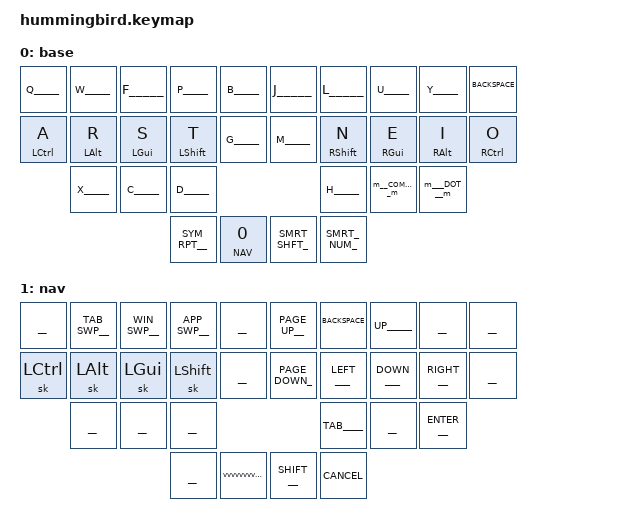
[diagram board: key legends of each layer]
/* source key position labels */
#include "zmk-helpers/key-labels/hummingbird.h"

#define MOUSE_IGNORED_KEYS LT1 LT3 RT0 RT1 RT2 RT3 RT4 RM1 RM2 RM3 RB1 RB2 RH0 RH1
#define REVERSE_SWAPPER RH0


/* source the base definitions */
#include "base.dtsi"

#define __LCTL__A__ &hml LCTL A
#define __LOPT__R__ &hml LALT R
#define __LGUI__S__ &hml LGUI S
#define __LSFT__T__ &hml LSHFT T
#define __RSFT__N__ &hmr RSHFT N
#define __RGUI__E__ &hmr RGUI E
#define __ROPT__I__ &hmr RALT I
#define __RCTL__O__ &hmr RCTL O

#define __SPC_NAV__ &lt_spc NAV 0
#define __SYM_RPT__ &lt SYM &key_repeat

ZMK_CONDITIONAL_LAYER(sys, SYM NUM, SYS)  // FN + NUM --> SYS

ZMK_LAYER(base,
//╭─────────────┬─────────────────────────────────────────┬─────────────╮ ╭─────────────┬───────────────────────────┬─────────────┬─────────────╮
    _____Q_____   _____W_____   _____F_____   _____P_____   _____B_____     _____J_____   _____L_____   _____U_____   _____Y_____   _BACKSPACE_ 
//├─────────────z─────────────────────────────────────────┼─────────────┤ ├─────────────┼─────────────┼─────────────┼─────────────┼─────────────┤
    __LCTL__A__   __LOPT__R__   __LGUI__S__   __LSFT__T__   _____G_____     _____M_____   __RSFT__N__   __RGUI__E__   __ROPT__I__   __RCTL__O__
//╰─────────────┼─────────────z─────────────v─────────────┼─────────────┤ ├─────────────┼─────────────k───────────────────────────┼─────────────╯
                  _____X_____   _____C_____   _____D_____                                 _____H_____   m__COMMA__m   m___DOT___m
//              ╰─────────────┴─────────────┴─────────────╯                             ╰─────────────┴─────────────┴─────────────╯
                                              __SYM_RPT__   __SPC_NAV__     _SMRT_SHFT_   _SMRT__NUM_                                                 
//                                          ╰─────────────┴─────────────╯ ╰─────────────┴─────────────╯
)

ZMK_LAYER(nav,
//╭─────────────┬─────────────q─────────────b─────────────┬─────────────╮ ╭─────────────┬───────────bcspc───────────┬─────────────┬─────────────╮
    ___________   __TAB_SWP__   __WIN_SWP__   __APP_SWP__   ___________     __PAGE_UP__   _BACKSPACE_   ____UP_____   ___________   ___________
//├─────────────z─────────────j─────────────f─────────────┼─────────────┤ ├─────────────┼─────────────┼─────────────┼─────────────┼─────────────┤
    &sk LCTRL     &sk LALT      &sk LGUI      &sk LSHFT     ___________     _PAGE_DOWN_   ___LEFT____   ___DOWN____   ___RIGHT___   ___________
//╰─────────────┼─────────────x─────────────v─────────────┼─────────────┤ ├─────────────┼─────────────,─────────────.─────────────┼─────────────╯
                  ___________   ___________   ___________                                 ____TAB____   ___________   ___ENTER___ 
//              ╰─────────────┴─────────────┴─────────────╯                             ╰─────────────┴─────────────┴─────────────╯
                                              ___________   vvvvvvvvvvv     ___SHIFT___    CANCEL
//                                          ╰─────────────┴─────────────╯ ╰─────────────┴─────────────╯
)

// ZMK_LAYER(fn,
// //╭──────╮ ╭─────────────┬─────────────┬─────────────┬─────────────┬─────────────╮ ╭──────╮ ╭─────────────┬─────────────┬─────────────┬─────────────┬─────────────╮ ╭──────╮
//     X_LT     &kp F12       &kp F7        &kp F8        &kp F9        ___             X_MT     ___           &kp C_PREV    &kp C_VOL_UP  &kp C_NEXT    &win_sleep      X_RT
// //├──────┤ ├─────────────┼─────────────┼─────────────┼─────────────┼─────────────┤ ├──────┤ ├─────────────┼─────────────┼─────────────┼─────────────┼─────────────┤ ├──────┤
//     X_LM     &hml LGUI F11 &hml LALT F4  &hml LSHFT F5 &hml LCTRL F6 ___             X_MM     ___           DSK_PREV      VOL_DOWN      DSK_NEXT      ___             X_RM
// //├──────┤ ├─────────────┼─────────────┼─────────────┼─────────────┼─────────────┤ ├──────┤ ├─────────────┼─────────────┼─────────────┼─────────────┼─────────────┤ ├──────┤
//     X_LB     &kp F10       &kp F1        &kp F2        &kp F3        ___             X_MB     PIN_APP       PIN_WIN       DSK_MGR       ___           ___             X_RB
// //├──────┤ ╰─────────────┼─────────────┴─────────────┼─────────────┼─────────────┤ ├──────┤ ├─────────────┼─────────────┼─────────────┴───────────────────────────╯ ├──────┤
//     X_LH                                               ___           ___             X_MH     &kp C_MUTE    &kp C_PP                                                  X_RH
// //╰──────╯                                           ╰─────────────┴─────────────╯ ╰──────╯ ╰─────────────┴─────────────╯                                           ╰──────╯
// )

// ZMK_LAYER(num,
// //╭──────╮ ╭─────────────┬─────────────┬─────────────┬─────────────┬─────────────╮ ╭──────╮ ╭─────────────┬─────────────┬─────────────┬─────────────┬─────────────╮ ╭──────╮
//     X_LT     ___           &kp N7        &kp N8        &kp N9        ___             X_MT     ___           ___           ___           ___           ___             X_RT
// //├──────┤ ├─────────────┼─────────────┼─────────────┼─────────────┼─────────────┤ ├──────┤ ├─────────────┼─────────────┼─────────────┼─────────────┼─────────────┤ ├──────┤
//     X_LM     &hml LGUI N0  &hml LALT N4  &hml LSHFT N5 &hml LCTRL N6 ___             X_MM     ___           ___           ___           ___           ___             X_RM
// //├──────┤ ├─────────────┼─────────────┼─────────────┼─────────────┼─────────────┤ ├──────┤ ├─────────────┼─────────────┼─────────────┼─────────────┼─────────────┤ ├──────┤
//     X_LB     ___           &kp N1        &kp N2        &kp N3        ___             X_MB     ___           ___           ___           ___           ___             X_RB
// //├──────┤ ╰─────────────┼─────────────┴─────────────┼─────────────┼─────────────┤ ├──────┤ ├─────────────┼─────────────┼─────────────┴───────────────────────────╯ ├──────┤
//     X_LH                                               ___           ___             X_MH     ___           ___                                                       X_RH
// //╰──────╯                                           ╰─────────────┴─────────────╯ ╰──────╯ ╰─────────────┴─────────────╯                                           ╰──────╯
// )

// ZMK_LAYER(sys,
// //╭──────╮ ╭─────────────┬─────────────┬─────────────┬─────────────┬─────────────╮ ╭──────╮ ╭─────────────┬─────────────┬─────────────┬─────────────┬─────────────╮ ╭──────╮
//     X_LT                                _BT_SEL_KEYS_                                X_MT     ___           ___           ___           ___           ___             X_RT
// //├──────┤ ├─────────────┼─────────────┼─────────────┼─────────────┼─────────────┤ ├──────┤ ├─────────────┼─────────────┼─────────────┼─────────────┼─────────────┤ ├──────┤
//     X_LM     ___           ___           ___           ___           &bootloader     X_MM     &bootloader   ___           ___           ___           ___             X_RM
// //├──────┤ ├─────────────┼─────────────┼─────────────┼─────────────┼─────────────┤ ├──────┤ ├─────────────┼─────────────┼─────────────┼─────────────┼─────────────┤ ├──────┤
//     X_LB     ___           ___           ___           ___           &sys_reset      X_MB     &sys_reset    ___           ___           ___           ___             X_RB
// //├──────┤ ╰─────────────┼─────────────┴─────────────┼─────────────┼─────────────┤ ├──────┤ ├─────────────┼─────────────┼─────────────┴───────────────────────────╯ ├──────┤
//     X_LH                                               ___           ___             X_MH     ___           ___                                                       X_RH
// //╰──────╯                                           ╰─────────────┴─────────────╯ ╰──────╯ ╰─────────────┴─────────────╯                                           ╰──────╯
// )

// ZMK_LAYER(mouse,
// //╭──────╮ ╭─────────────┬─────────────┬─────────────┬─────────────┬─────────────╮ ╭──────╮ ╭─────────────┬─────────────┬─────────────┬─────────────┬─────────────╮ ╭──────╮
//     X_LT     ___           ___           ___           ___           ___             X_MT     U_WH_L        U_WH_D        U_MS_U         U_WH_U       U_WH_R          X_RT
// //├──────┤ ├─────────────┼─────────────┼─────────────┼─────────────┼─────────────┤ ├──────┤ ├─────────────┼─────────────┼─────────────┼─────────────┼─────────────┤ ├──────┤
//     X_LM     ___           ___           ___           ___           ___             X_MM     ___           U_MS_L        U_MS_D         U_MS_R       ___             X_RM
// //├──────┤ ├─────────────┼─────────────┼─────────────┼─────────────┼─────────────┤ ├──────┤ ├─────────────┼─────────────┼─────────────┼─────────────┼─────────────┤ ├──────┤
//     X_LB     ___           ___           ___           ___           ___             X_MB     ___           &mkp MB4      &mkp MCLK      &mkp MB5     ___             X_RB
// //├──────┤ ╰─────────────┼─────────────┴─────────────┼─────────────┼─────────────┤ ├──────┤ ├─────────────┼─────────────┼─────────────┴───────────────────────────╯ ├──────┤
//     X_LH                                               ___           ___             X_MH     &mkp LCLK     &mkp RCLK                                                 X_RH
// //╰──────╯                                           ╰─────────────┴─────────────╯ ╰──────╯ ╰─────────────┴─────────────╯                                           ╰──────╯
// )

/*****************************************************************************
    Sample Layer
 *****************************************************************************

ZMK_LAYER(layer_name,
//╭─────────────┬─────────────┬─────────────┬─────────────┬─────────────╮ ╭─────────────┬─────────────┬─────────────┬─────────────┬─────────────╮
    ___________   ___________   ___________   ___________   ___________     ___________   ___________   ___________   ___________   ___________
//├─────────────┼─────────────┼─────────────┼─────────────┼─────────────┤ ├─────────────┼─────────────┼─────────────┼─────────────┼─────────────┤
    ___________   ___________   ___________   ___________   ___________     ___________   ___________   ___________   ___________   ___________
//╰─────────────┼─────────────┼─────────────┼─────────────┼─────────────┤ ├─────────────┼─────────────┼─────────────┼─────────────┼─────────────╯
                  ___________   ___________   ___________                                 ___________   ___________   ___________
//              ╰─────────────┴─────────────┴─────────────╯                             ╰─────────────┴─────────────┴─────────────╯
                                              ___________   ___________     ___________   ___________
//                                          ╰─────────────┴─────────────╯ ╰─────────────┴─────────────╯
)

******************************************************************************/
